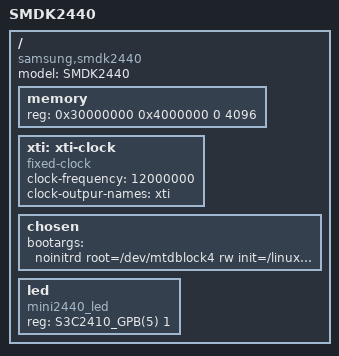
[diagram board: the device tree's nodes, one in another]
// SPDX-License-Identifier: GPL-2.0
/*
 * SAMSUNG SMDK2440 board device tree source
 *
 * Copyright (c) 2018 flinn <flinn682@foxmail.com>
 * dtc -I dtb -O dts -o s3c2440-mini2440.dts s3c2440-mini2440.dtb
 */

#define S3C2410_GPA(_nr)	((0<<16) + (_nr))
#define S3C2410_GPB(_nr)	((1<<16) + (_nr))
#define S3C2410_GPC(_nr)	((2<<16) + (_nr))
#define S3C2410_GPD(_nr)	((3<<16) + (_nr))
#define S3C2410_GPE(_nr)	((4<<16) + (_nr))
#define S3C2410_GPF(_nr)	((5<<16) + (_nr))
#define S3C2410_GPG(_nr)	((6<<16) + (_nr))
#define S3C2410_GPH(_nr)	((7<<16) + (_nr))
#define S3C2410_GPJ(_nr)	((8<<16) + (_nr))
#define S3C2410_GPK(_nr)	((9<<16) + (_nr))
#define S3C2410_GPL(_nr)	((10<<16) + (_nr))
#define S3C2410_GPM(_nr)	((11<<16) + (_nr))

/dts-v1/;

/{
	model = "SMDK2440";
	compatible = "samsung,smdk2440";

	#address-cells = <1>;
	#size-cells = <1>;

	memory {  /* /memory */
		device_type = "memory";
		reg =  <0x30000000 0x4000000 0 4096>;		
	};
	
	xti:xti-clock {
		compatible = "fixed-clock";
		clock-frequency = <12000000>;
		clock-outpur-names = "xti";
		#clock-cells = <0>;
	};

	chosen {
		bootargs = "noinitrd root=/dev/mtdblock4 rw init=/linuxrc console=ttySAC0,115200";
	};

	led {
		compatible = "mini2440_led";
		reg = <S3C2410_GPB(5) 1>;
	};
};
